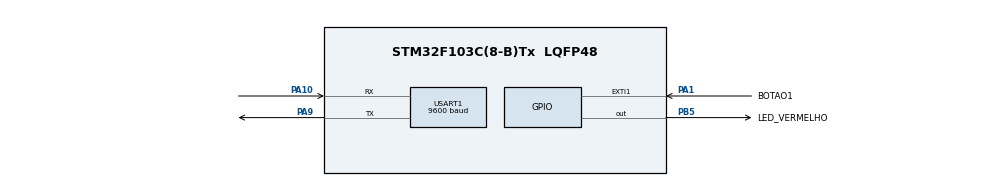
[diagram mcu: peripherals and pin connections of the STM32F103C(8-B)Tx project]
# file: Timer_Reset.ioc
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Mcu.Family=STM32F1
PA10.Mode=Asynchronous
USART1.BaudRate=9600
VP_SYS_VS_ND.Mode=No_Debug
ProjectManager.StackSize=0x400
PA9.Mode=Asynchronous
NVIC.EXTI1_IRQn=true\:0\:0\:false\:false\:true\:true\:true
ProjectManager.TargetToolchain=STM32CubeIDE
PA9.Signal=USART1_TX
PA1.Signal=GPXTI1
board=custom
RCC.APB2Freq_Value=8000000
VP_TIM2_VS_ClockSourceINT.Mode=Internal
PA1.GPIO_Label=BOTAO1
TIM2.Period=9999
Mcu.Name=STM32F103C(8-B)Tx
PB5.Signal=GPIO_Output
Mcu.Package=LQFP48
TIM2.Prescaler=7999
USART1.VirtualMode=VM_ASYNC
PA10.Signal=USART1_RX
ProjectManager.HeapSize=0x200
NVIC.PriorityGroup=NVIC_PRIORITYGROUP_4
PB5.GPIO_Label=LED_VERMELHO
RCC.APB1Freq_Value=8000000

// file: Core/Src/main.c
/* USER CODE BEGIN Header */
/**
  ******************************************************************************
  * @file           : main.c
  * @brief          : Main program body
  ******************************************************************************
  * @attention
  *
  * <h2><center>&copy; Copyright (c) 2021 STMicroelectronics.
  * All rights reserved.</center></h2>
  *
  * This software component is licensed by ST under BSD 3-Clause license,
  * the "License"; You may not use this file except in compliance with the
  * License. You may obtain a copy of the License at:
  *                        opensource.org/licenses/BSD-3-Clause
  *
  ******************************************************************************
  */
/* USER CODE END Header */
#include "main.h"

/* USER CODE BEGIN Includes */
#include<stdio.h>
#include<string.h>

/* USER CODE END Includes */

TIM_HandleTypeDef htim2;

UART_HandleTypeDef huart1;

/* USER CODE BEGIN PV */
uint16_t timer_value;
char DadoTX[20];

/* USER CODE END PV */

void SystemClock_Config(void);
static void MX_GPIO_Init(void);
static void MX_TIM2_Init(void);
static void MX_USART1_UART_Init(void);

/* USER CODE BEGIN 0 */

// toda vez que o Botao1 (PA1) for acionado o LED vermelho (PB5) irá inverter seu estado
// e a contagem do timer2 será reiniciada
void HAL_GPIO_EXTI_Callback(uint16_t GPIO_Pin)
{
	if(GPIO_Pin == BOTAO1_Pin)
	{
		HAL_GPIO_TogglePin(LED_VERMELHO_GPIO_Port, LED_VERMELHO_Pin);
		__HAL_TIM_SET_COUNTER(&htim2, 0);
	}
}

/* USER CODE END 0 */

int main(void)
{

  /* MCU Configuration--------------------------------------------------------*/

  /* Reset of all peripherals, Initializes the Flash interface and the Systick. */
  HAL_Init();

  /* Configure the system clock */
  SystemClock_Config();

  /* Initialize all configured peripherals */
  MX_GPIO_Init();
  MX_TIM2_Init();
  MX_USART1_UART_Init();
  /* USER CODE BEGIN 2 */

  // incializa o timer
  HAL_TIM_Base_Start(&htim2);

  // inicializa a UART
  HAL_UART_Init(&huart1);

  // habilita interrupção no PA1 para o botão
  HAL_NVIC_EnableIRQ(EXTI1_IRQn);
  /* USER CODE END 2 */

  /* Infinite loop */
  while (1)
  {

    /* USER CODE BEGIN 3 */
	sprintf(DadoTX, "%lu\r\n", __HAL_TIM_GET_COUNTER(&htim2));

	// vai mandar o valor atual do timer pela UART até ele atingir seu valor máximo e reinicializar
	HAL_UART_Transmit(&huart1, (uint8_t *) DadoTX, strlen(DadoTX), HAL_MAX_DELAY);
  }
  /* USER CODE END 3 */
}

void SystemClock_Config(void)
{
  RCC_OscInitTypeDef RCC_OscInitStruct = {0};
  RCC_ClkInitTypeDef RCC_ClkInitStruct = {0};

  /** Initializes the RCC Oscillators according to the specified parameters
  * in the RCC_OscInitTypeDef structure.
  */
  RCC_OscInitStruct.OscillatorType = RCC_OSCILLATORTYPE_HSI;
  RCC_OscInitStruct.HSIState = RCC_HSI_ON;
  RCC_OscInitStruct.HSICalibrationValue = RCC_HSICALIBRATION_DEFAULT;
  RCC_OscInitStruct.PLL.PLLState = RCC_PLL_NONE;
  if (HAL_RCC_OscConfig(&RCC_OscInitStruct) != HAL_OK)
  {
    Error_Handler();
  }
  /** Initializes the CPU, AHB and APB buses clocks
  */
  RCC_ClkInitStruct.ClockType = RCC_CLOCKTYPE_HCLK|RCC_CLOCKTYPE_SYSCLK
                              |RCC_CLOCKTYPE_PCLK1|RCC_CLOCKTYPE_PCLK2;
  RCC_ClkInitStruct.SYSCLKSource = RCC_SYSCLKSOURCE_HSI;
  RCC_ClkInitStruct.AHBCLKDivider = RCC_SYSCLK_DIV1;
  RCC_ClkInitStruct.APB1CLKDivider = RCC_HCLK_DIV1;
  RCC_ClkInitStruct.APB2CLKDivider = RCC_HCLK_DIV1;

  if (HAL_RCC_ClockConfig(&RCC_ClkInitStruct, FLASH_LATENCY_0) != HAL_OK)
  {
    Error_Handler();
  }
}

static void MX_TIM2_Init(void)
{

  TIM_ClockConfigTypeDef sClockSourceConfig = {0};
  TIM_MasterConfigTypeDef sMasterConfig = {0};

  htim2.Instance = TIM2;
  htim2.Init.Prescaler = 7999;
  htim2.Init.CounterMode = TIM_COUNTERMODE_UP;
  htim2.Init.Period = 9999;
  htim2.Init.ClockDivision = TIM_CLOCKDIVISION_DIV1;
  htim2.Init.AutoReloadPreload = TIM_AUTORELOAD_PRELOAD_DISABLE;
  if (HAL_TIM_Base_Init(&htim2) != HAL_OK)
  {
    Error_Handler();
  }
  sClockSourceConfig.ClockSource = TIM_CLOCKSOURCE_INTERNAL;
  if (HAL_TIM_ConfigClockSource(&htim2, &sClockSourceConfig) != HAL_OK)
  {
    Error_Handler();
  }
  sMasterConfig.MasterOutputTrigger = TIM_TRGO_RESET;
  sMasterConfig.MasterSlaveMode = TIM_MASTERSLAVEMODE_DISABLE;
  if (HAL_TIMEx_MasterConfigSynchronization(&htim2, &sMasterConfig) != HAL_OK)
  {
    Error_Handler();
  }

}

static void MX_USART1_UART_Init(void)
{

  huart1.Instance = USART1;
  huart1.Init.BaudRate = 9600;
  huart1.Init.WordLength = UART_WORDLENGTH_8B;
  huart1.Init.StopBits = UART_STOPBITS_1;
  huart1.Init.Parity = UART_PARITY_NONE;
  huart1.Init.Mode = UART_MODE_TX_RX;
  huart1.Init.HwFlowCtl = UART_HWCONTROL_NONE;
  huart1.Init.OverSampling = UART_OVERSAMPLING_16;
  if (HAL_UART_Init(&huart1) != HAL_OK)
  {
    Error_Handler();
  }

}

static void MX_GPIO_Init(void)
{
  GPIO_InitTypeDef GPIO_InitStruct = {0};

  /* GPIO Ports Clock Enable */
  __HAL_RCC_GPIOA_CLK_ENABLE();
  __HAL_RCC_GPIOB_CLK_ENABLE();

  /*Configure GPIO pin Output Level */
  HAL_GPIO_WritePin(LED_VERMELHO_GPIO_Port, LED_VERMELHO_Pin, GPIO_PIN_RESET);

  /*Configure GPIO pin : BOTAO1_Pin */
  GPIO_InitStruct.Pin = BOTAO1_Pin;
  GPIO_InitStruct.Mode = GPIO_MODE_IT_RISING;
  GPIO_InitStruct.Pull = GPIO_NOPULL;
  HAL_GPIO_Init(BOTAO1_GPIO_Port, &GPIO_InitStruct);

  /*Configure GPIO pin : LED_VERMELHO_Pin */
  GPIO_InitStruct.Pin = LED_VERMELHO_Pin;
  GPIO_InitStruct.Mode = GPIO_MODE_OUTPUT_PP;
  GPIO_InitStruct.Pull = GPIO_NOPULL;
  GPIO_InitStruct.Speed = GPIO_SPEED_FREQ_LOW;
  HAL_GPIO_Init(LED_VERMELHO_GPIO_Port, &GPIO_InitStruct);

  /* EXTI interrupt init*/
  HAL_NVIC_SetPriority(EXTI1_IRQn, 0, 0);
  HAL_NVIC_EnableIRQ(EXTI1_IRQn);

}

void Error_Handler(void)
{
  __disable_irq();
  while (1)
  {
  }
}

/************************ (C) COPYRIGHT STMicroelectronics *****END OF FILE****/
